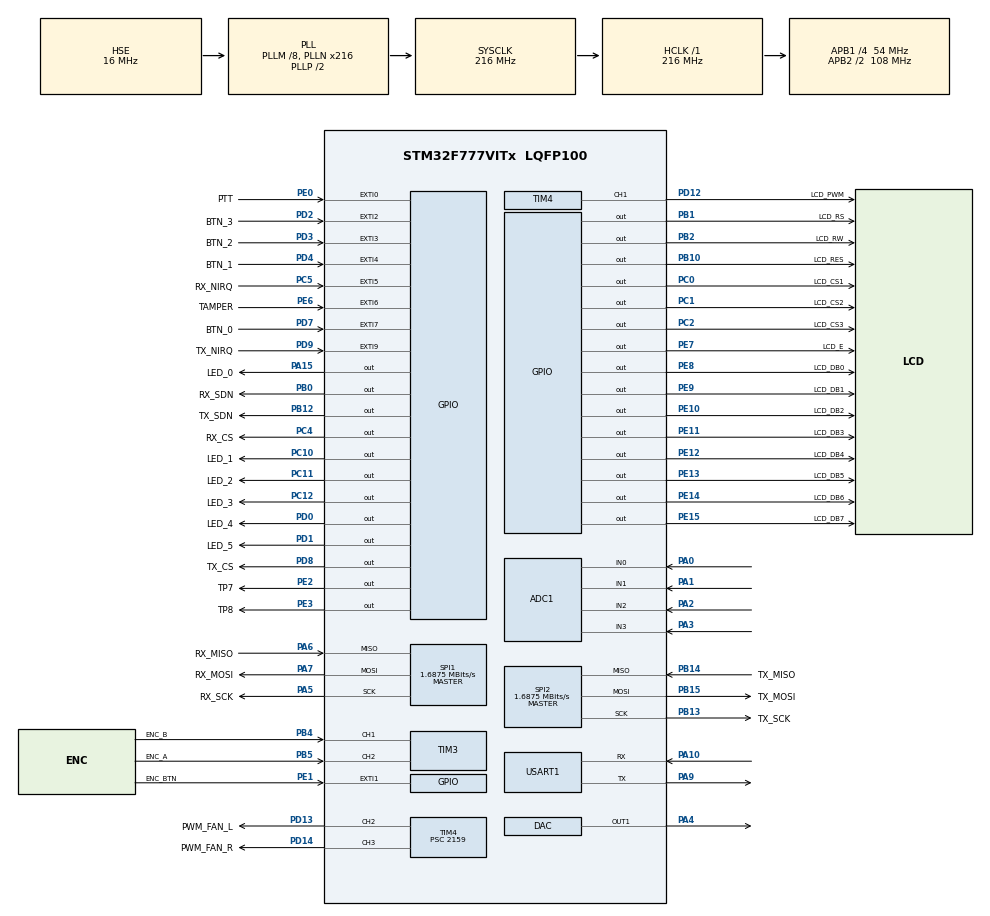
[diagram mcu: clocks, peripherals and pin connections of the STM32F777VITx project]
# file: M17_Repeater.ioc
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ADC1.Channel-0\#ChannelRegularConversion=ADC_CHANNEL_0
ADC1.NbrOfConversionFlag=1
ADC1.Rank-0\#ChannelRegularConversion=1
ADC1.SamplingTime-0\#ChannelRegularConversion=ADC_SAMPLETIME_3CYCLES
ADC1.master=1
Dma.Request0=USART1_TX
Dma.USART1_TX.0.Direction=DMA_MEMORY_TO_PERIPH
Dma.USART1_TX.0.FIFOMode=DMA_FIFOMODE_DISABLE
Dma.USART1_TX.0.Instance=DMA2_Stream7
Dma.USART1_TX.0.MemDataAlignment=DMA_MDATAALIGN_BYTE
Dma.USART1_TX.0.MemInc=DMA_MINC_ENABLE
Dma.USART1_TX.0.Mode=DMA_NORMAL
Dma.USART1_TX.0.PeriphDataAlignment=DMA_PDATAALIGN_BYTE
Dma.USART1_TX.0.PeriphInc=DMA_PINC_DISABLE
Dma.USART1_TX.0.Priority=DMA_PRIORITY_HIGH
Mcu.Family=STM32F7
Mcu.Name=STM32F777VITx
Mcu.Package=LQFP100
NVIC.DMA2_Stream7_IRQn=true\:0\:0\:false\:false\:true\:false
NVIC.EXTI0_IRQn=true\:0\:0\:false\:false\:true\:true
NVIC.EXTI1_IRQn=true\:0\:0\:false\:false\:true\:true
NVIC.EXTI2_IRQn=true\:0\:0\:false\:false\:true\:true
NVIC.EXTI3_IRQn=true\:0\:0\:false\:false\:true\:true
NVIC.EXTI4_IRQn=true\:0\:0\:false\:false\:true\:true
NVIC.EXTI9_5_IRQn=true\:0\:0\:false\:false\:true\:true
NVIC.PriorityGroup=NVIC_PRIORITYGROUP_4
NVIC.TIM6_DAC_IRQn=true\:0\:0\:false\:false\:true\:true
NVIC.USART1_IRQn=true\:0\:0\:false\:false\:true\:true
PA0/WKUP.Signal=ADCx_IN0
PA1.Signal=ADCx_IN1
PA10.Mode=Asynchronous
PA10.Signal=USART1_RX
PA13.Mode=Serial_Wire
PA13.Signal=SYS_JTMS-SWDIO
PA14.Mode=Serial_Wire
PA14.Signal=SYS_JTCK-SWCLK
PA15.GPIO_Label=LED_0
PA15.Signal=GPIO_Output
PA2.Signal=ADCx_IN2
PA3.Signal=ADCx_IN3
PA4.Signal=COMP_DAC1_group
PA5.GPIO_Label=RX_SCK
PA5.Mode=Full_Duplex_Master
PA5.Signal=SPI1_SCK
PA6.GPIO_Label=RX_MISO
PA6.Mode=Full_Duplex_Master
PA6.Signal=SPI1_MISO
PA7.GPIO_Label=RX_MOSI
PA7.Mode=Full_Duplex_Master
PA7.Signal=SPI1_MOSI
PA9.Mode=Asynchronous
PA9.Signal=USART1_TX
PB0.GPIO_Label=RX_SDN
PB0.GPIO_ModeDefaultOutputPP=GPIO_MODE_OUTPUT_PP
PB0.GPIO_PuPd=GPIO_NOPULL
PB0.GPIO_Speed=GPIO_SPEED_FREQ_VERY_HIGH
PB0.PinState=GPIO_PIN_SET
PB0.Signal=GPIO_Output
PB1.GPIO_Label=LCD_RS
PB1.GPIO_ModeDefaultOutputPP=GPIO_MODE_OUTPUT_PP
PB1.GPIO_PuPd=GPIO_NOPULL
PB1.GPIO_Speed=GPIO_SPEED_FREQ_VERY_HIGH
PB1.Signal=GPIO_Output
PB10.GPIO_Label=LCD_RES
PB10.GPIO_ModeDefaultOutputPP=GPIO_MODE_OUTPUT_PP
PB10.GPIO_PuPd=GPIO_NOPULL
PB10.GPIO_Speed=GPIO_SPEED_FREQ_VERY_HIGH
PB10.Signal=GPIO_Output
PB12.GPIO_Label=TX_SDN
PB12.GPIO_ModeDefaultOutputPP=GPIO_MODE_OUTPUT_PP
PB12.GPIO_PuPd=GPIO_NOPULL
PB12.GPIO_Speed=GPIO_SPEED_FREQ_VERY_HIGH
PB12.PinState=GPIO_PIN_SET
PB12.Signal=GPIO_Output
PB13.GPIO_Label=TX_SCK
PB13.Mode=Full_Duplex_Master
PB13.Signal=SPI2_SCK
PB14.GPIO_Label=TX_MISO
PB14.Mode=Full_Duplex_Master
PB14.Signal=SPI2_MISO
PB15.GPIO_Label=TX_MOSI
PB15.Mode=Full_Duplex_Master
PB15.Signal=SPI2_MOSI
PB2.GPIO_Label=LCD_RW
PB2.GPIO_ModeDefaultOutputPP=GPIO_MODE_OUTPUT_PP
PB2.GPIO_PuPd=GPIO_NOPULL
PB2.GPIO_Speed=GPIO_SPEED_FREQ_VERY_HIGH
PB2.Signal=GPIO_Output
PB4.GPIO_Label=ENC_B
PB4.Signal=S_TIM3_CH1
PB5.GPIO_Label=ENC_A
PB5.Signal=S_TIM3_CH2
PC0.GPIO_Label=LCD_CS1
PC0.GPIO_Speed=GPIO_SPEED_FREQ_VERY_HIGH
PC0.Signal=GPIO_Output
PC1.GPIO_Label=LCD_CS2
PC1.GPIO_Speed=GPIO_SPEED_FREQ_VERY_HIGH
PC1.Signal=GPIO_Output
PC10.GPIO_Label=LED_1
PC10.Signal=GPIO_Output
PC11.GPIO_Label=LED_2
PC11.Signal=GPIO_Output
PC12.GPIO_Label=LED_3
PC12.Signal=GPIO_Output
PC2.GPIO_Label=LCD_CS3
PC2.GPIO_Speed=GPIO_SPEED_FREQ_VERY_HIGH
PC2.Signal=GPIO_Output
PC4.GPIO_Label=RX_CS
PC4.GPIO_Speed=GPIO_SPEED_FREQ_VERY_HIGH
PC4.PinState=GPIO_PIN_SET
PC4.Signal=GPIO_Output
PC5.GPIO_Label=RX_NIRQ
PC5.GPIO_ModeDefaultEXTI=GPIO_MODE_IT_FALLING
PC5.Signal=GPXTI5
PD0.GPIO_Label=LED_4
PD0.Signal=GPIO_Output
PD1.GPIO_Label=LED_5
PD1.Signal=GPIO_Output
PD12.GPIO_Label=LCD_PWM
PD12.GPIO_Speed=GPIO_SPEED_FREQ_HIGH
PD12.Signal=S_TIM4_CH1
PD13.GPIO_Label=PWM_FAN_L
PD13.GPIO_ModeDefaultPP=GPIO_MODE_AF_PP
PD13.GPIO_PuPd=GPIO_NOPULL
PD13.GPIO_Speed=GPIO_SPEED_FREQ_HIGH
PD13.Signal=S_TIM4_CH2
PD14.GPIO_Label=PWM_FAN_R
PD14.GPIO_ModeDefaultPP=GPIO_MODE_AF_PP
PD14.GPIO_PuPd=GPIO_NOPULL
PD14.GPIO_Speed=GPIO_SPEED_FREQ_HIGH
PD14.Signal=S_TIM4_CH3
PD2.GPIO_Label=BTN_3
PD2.GPIO_ModeDefaultEXTI=GPIO_MODE_IT_FALLING
PD2.GPIO_PuPd=GPIO_NOPULL
PD2.Signal=GPXTI2
PD3.GPIO_Label=BTN_2
PD3.GPIO_ModeDefaultEXTI=GPIO_MODE_IT_FALLING
PD3.GPIO_PuPd=GPIO_NOPULL
PD3.Signal=GPXTI3
PD4.GPIO_Label=BTN_1
PD4.GPIO_ModeDefaultEXTI=GPIO_MODE_IT_FALLING
PD4.GPIO_PuPd=GPIO_NOPULL
PD4.Signal=GPXTI4
PD7.GPIO_Label=BTN_0
PD7.GPIO_ModeDefaultEXTI=GPIO_MODE_IT_FALLING
PD7.GPIO_PuPd=GPIO_NOPULL
PD7.Signal=GPXTI7
PD8.GPIO_Label=TX_CS
PD8.GPIO_Speed=GPIO_SPEED_FREQ_VERY_HIGH
PD8.PinState=GPIO_PIN_SET
PD8.Signal=GPIO_Output
PD9.GPIO_Label=TX_NIRQ
PD9.GPIO_ModeDefaultEXTI=GPIO_MODE_IT_FALLING
PD9.Signal=GPXTI9
PE0.GPIO_Label=PTT
PE0.GPIO_ModeDefaultEXTI=GPIO_MODE_IT_FALLING
PE0.Signal=GPXTI0
PE1.GPIO_Label=ENC_BTN
PE1.GPIO_ModeDefaultEXTI=GPIO_MODE_IT_FALLING
PE1.Signal=GPXTI1
PE10.GPIO_Label=LCD_DB2
PE10.GPIO_ModeDefaultOutputPP=GPIO_MODE_OUTPUT_PP
PE10.GPIO_PuPd=GPIO_NOPULL
PE10.GPIO_Speed=GPIO_SPEED_FREQ_VERY_HIGH
PE10.PinState=GPIO_PIN_RESET
PE10.Signal=GPIO_Output
PE11.GPIO_Label=LCD_DB3
PE11.GPIO_ModeDefaultOutputPP=GPIO_MODE_OUTPUT_PP
PE11.GPIO_PuPd=GPIO_NOPULL
PE11.GPIO_Speed=GPIO_SPEED_FREQ_VERY_HIGH
PE11.PinState=GPIO_PIN_RESET
PE11.Signal=GPIO_Output
PE12.GPIO_Label=LCD_DB4
PE12.GPIO_ModeDefaultOutputPP=GPIO_MODE_OUTPUT_PP
PE12.GPIO_PuPd=GPIO_NOPULL
PE12.GPIO_Speed=GPIO_SPEED_FREQ_VERY_HIGH
PE12.PinState=GPIO_PIN_RESET
PE12.Signal=GPIO_Output
PE13.GPIO_Label=LCD_DB5
PE13.GPIO_ModeDefaultOutputPP=GPIO_MODE_OUTPUT_PP
PE13.GPIO_PuPd=GPIO_NOPULL
PE13.GPIO_Speed=GPIO_SPEED_FREQ_VERY_HIGH
PE13.PinState=GPIO_PIN_RESET
PE13.Signal=GPIO_Output
PE14.GPIO_Label=LCD_DB6
PE14.GPIO_ModeDefaultOutputPP=GPIO_MODE_OUTPUT_PP
PE14.GPIO_PuPd=GPIO_NOPULL
PE14.GPIO_Speed=GPIO_SPEED_FREQ_VERY_HIGH
PE14.PinState=GPIO_PIN_RESET
PE14.Signal=GPIO_Output
PE15.GPIO_Label=LCD_DB7
PE15.GPIO_ModeDefaultOutputPP=GPIO_MODE_OUTPUT_PP
PE15.GPIO_PuPd=GPIO_NOPULL
PE15.GPIO_Speed=GPIO_SPEED_FREQ_VERY_HIGH
PE15.PinState=GPIO_PIN_RESET
PE15.Signal=GPIO_Output
PE2.GPIO_Label=TP7
PE2.Signal=GPIO_Output
PE3.GPIO_Label=TP8
PE3.Signal=GPIO_Output
PE6.GPIO_Label=TAMPER
PE6.GPIO_ModeDefaultEXTI=GPIO_MODE_IT_RISING_FALLING
PE6.Signal=GPXTI6
PE7.GPIO_Label=LCD_E
PE7.GPIO_ModeDefaultOutputPP=GPIO_MODE_OUTPUT_PP
PE7.GPIO_PuPd=GPIO_NOPULL
PE7.GPIO_Speed=GPIO_SPEED_FREQ_VERY_HIGH
PE7.PinState=GPIO_PIN_RESET
PE7.Signal=GPIO_Output
PE8.GPIO_Label=LCD_DB0
PE8.GPIO_ModeDefaultOutputPP=GPIO_MODE_OUTPUT_PP
PE8.GPIO_PuPd=GPIO_NOPULL
PE8.GPIO_Speed=GPIO_SPEED_FREQ_VERY_HIGH
PE8.PinState=GPIO_PIN_RESET
PE8.Signal=GPIO_Output
PE9.GPIO_Label=LCD_DB1
PE9.GPIO_ModeDefaultOutputPP=GPIO_MODE_OUTPUT_PP
PE9.GPIO_PuPd=GPIO_NOPULL
PE9.GPIO_Speed=GPIO_SPEED_FREQ_VERY_HIGH
PE9.PinState=GPIO_PIN_RESET
PE9.Signal=GPIO_Output
PH0/OSC_IN.Mode=HSE-External-Clock-Source
PH0/OSC_IN.Signal=RCC_OSC_IN
PH1/OSC_OUT.Mode=HSE-External-Clock-Source
PH1/OSC_OUT.Signal=RCC_OSC_OUT
ProjectManager.HeapSize=0x200
ProjectManager.StackSize=0x400
ProjectManager.TargetToolchain=SW4STM32
RCC.AHBFreq_Value=216000000
RCC.APB1CLKDivider=RCC_HCLK_DIV4
RCC.APB1Freq_Value=54000000
RCC.APB1TimFreq_Value=108000000
RCC.APB2CLKDivider=RCC_HCLK_DIV2
RCC.APB2Freq_Value=108000000
RCC.APB2TimFreq_Value=216000000
RCC.CortexFreq_Value=216000000
RCC.HCLKFreq_Value=216000000
RCC.HSE_VALUE=16000000
RCC.HSI_VALUE=16000000
RCC.LSE_VALUE=32768
RCC.PLLM=8
RCC.PLLN=216
RCC.PLLSourceVirtual=RCC_PLLSOURCE_HSE
RCC.SYSCLKFreq_VALUE=216000000
RCC.SYSCLKSource=RCC_SYSCLKSOURCE_PLLCLK
RCC.USBFreq_Value=216000000
RCC.VCOOutputFreq_Value=432000000
SH.ADCx_IN0.0=ADC1_IN0,IN0
SH.ADCx_IN1.0=ADC1_IN1,IN1
SH.ADCx_IN2.0=ADC1_IN2,IN2
SH.ADCx_IN3.0=ADC1_IN3,IN3
SH.COMP_DAC1_group.0=DAC_OUT1,DAC_OUT1
SH.S_TIM3_CH1.0=TIM3_CH1,Encoder_Interface
SH.S_TIM3_CH2.0=TIM3_CH2,Encoder_Interface
SH.S_TIM4_CH1.0=TIM4_CH1,PWM Generation1 CH1
SH.S_TIM4_CH2.0=TIM4_CH2,PWM Generation2 CH2
SH.S_TIM4_CH3.0=TIM4_CH3,PWM Generation3 CH3
SPI1.BaudRatePrescaler=SPI_BAUDRATEPRESCALER_64
SPI1.CalculateBaudRate=1.6875 MBits/s
SPI1.DataSize=SPI_DATASIZE_8BIT
SPI1.Direction=SPI_DIRECTION_2LINES
SPI1.Mode=SPI_MODE_MASTER
SPI1.NSSPMode=SPI_NSS_PULSE_DISABLE
SPI1.VirtualType=VM_MASTER
SPI2.BaudRatePrescaler=SPI_BAUDRATEPRESCALER_32
SPI2.CalculateBaudRate=1.6875 MBits/s
SPI2.DataSize=SPI_DATASIZE_8BIT
SPI2.Direction=SPI_DIRECTION_2LINES
SPI2.Mode=SPI_MODE_MASTER
SPI2.NSSPMode=SPI_NSS_PULSE_DISABLE
SPI2.VirtualType=VM_MASTER
TIM4.Channel-PWM\ Generation1\ CH1=TIM_CHANNEL_1
TIM4.Channel-PWM\ Generation2\ CH2=TIM_CHANNEL_2
TIM4.Channel-PWM\ Generation3\ CH3=TIM_CHANNEL_3
TIM4.Period=99
TIM4.Prescaler=2159
TIM4.Pulse-PWM\ Generation1\ CH1=0
TIM6.Period=1999
TIM6.Prescaler=21599
TIM6.TIM_MasterOutputTrigger=TIM_TRGO_UPDATE
USART1.VirtualMode-Asynchronous=VM_ASYNC
VP_TIM4_VS_ClockSourceINT.Mode=Internal
VP_TIM6_VS_ClockSourceINT.Mode=Enable_Timer
board=custom

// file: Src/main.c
/**
  ******************************************************************************
  * @file           : main.c
  * @brief          : Main program body
  ******************************************************************************
  ** This notice applies to any and all portions of this file
  * that are not between comment pairs USER CODE BEGIN and
  * USER CODE END. Other portions of this file, whether
  * inserted by the user or by software development tools
  * are owned by their respective copyright owners.
  *
  * COPYRIGHT(c) 2019 STMicroelectronics
  *
  * Redistribution and use in source and binary forms, with or without modification,
  * are permitted provided that the following conditions are met:
  *   1. Redistributions of source code must retain the above copyright notice,
  *      this list of conditions and the following disclaimer.
  *   2. Redistributions in binary form must reproduce the above copyright notice,
  *      this list of conditions and the following disclaimer in the documentation
  *      and/or other materials provided with the distribution.
  *   3. Neither the name of STMicroelectronics nor the names of its contributors
  *      may be used to endorse or promote products derived from this software
  *      without specific prior written permission.
  *
  * THIS SOFTWARE IS PROVIDED BY THE COPYRIGHT HOLDERS AND CONTRIBUTORS "AS IS"
  * AND ANY EXPRESS OR IMPLIED WARRANTIES, INCLUDING, BUT NOT LIMITED TO, THE
  * IMPLIED WARRANTIES OF MERCHANTABILITY AND FITNESS FOR A PARTICULAR PURPOSE ARE
  * DISCLAIMED. IN NO EVENT SHALL THE COPYRIGHT HOLDER OR CONTRIBUTORS BE LIABLE
  * FOR ANY DIRECT, INDIRECT, INCIDENTAL, SPECIAL, EXEMPLARY, OR CONSEQUENTIAL
  * DAMAGES (INCLUDING, BUT NOT LIMITED TO, PROCUREMENT OF SUBSTITUTE GOODS OR
  * SERVICES; LOSS OF USE, DATA, OR PROFITS; OR BUSINESS INTERRUPTION) HOWEVER
  * CAUSED AND ON ANY THEORY OF LIABILITY, WHETHER IN CONTRACT, STRICT LIABILITY,
  * OR TORT (INCLUDING NEGLIGENCE OR OTHERWISE) ARISING IN ANY WAY OUT OF THE USE
  * OF THIS SOFTWARE, EVEN IF ADVISED OF THE POSSIBILITY OF SUCH DAMAGE.
  *
  ******************************************************************************
  */
#include "main.h"
#include "stm32f7xx_hal.h"

/* USER CODE BEGIN Includes */
#include "font.h"

#include "radio_config.h"

#define	FRAMESIZE		160*2					//20+20=40ms frame
#define	RAW_BYTES		8*2
#define	CRC_LEN			2
#define	ENC_LEN			(RAW_BYTES)*2
#define	PLOAD_LEN		93

#define	DC_OFFSET		2040					//input signal DC offset

#define	MAX_TX_POWER	0x7F					//+20dBm

#define SPLIT			7600000UL				//TX-RX split

#define UART_BUFF_LEN	130						//UART1 buffer length
/* USER CODE END Includes */

ADC_HandleTypeDef hadc1;

DAC_HandleTypeDef hdac;

SPI_HandleTypeDef hspi1;
SPI_HandleTypeDef hspi2;

TIM_HandleTypeDef htim3;
TIM_HandleTypeDef htim4;
TIM_HandleTypeDef htim6;

UART_HandleTypeDef huart1;
DMA_HandleTypeDef hdma_usart1_tx;

/* USER CODE BEGIN PV */
/* Private variables ---------------------------------------------------------*/
//Si 446x RELATED
const uint8_t config[] = RADIO_CONFIGURATION_DATA_ARRAY;	//config
volatile uint8_t RX_ints[8];								//interrupts
volatile uint8_t r_initd=0;									//RX initialized?

volatile uint8_t rcv_buff[PLOAD_LEN];						//Si RX buffer

//main
volatile uint32_t tx_freq=439075000;						//TX frequency in Hz
volatile uint32_t rx_freq=431475000;						//RX

//QSO
volatile uint32_t last_id_from=0;
volatile uint32_t last_id_to=0;
volatile uint8_t  content_type=0;
volatile uint8_t  encr_type=0;

//UART
volatile uint8_t rx_buff[UART_BUFF_LEN];
volatile uint8_t tx_buff[UART_BUFF_LEN];
volatile uint8_t rx_cnt=0;									//where in rx buffer are we?

//TIMERS
volatile uint8_t tim_6_initd=0;								//first tim6 irq cleared?
/* USER CODE END PV */

void SystemClock_Config(void);
static void MX_GPIO_Init(void);
static void MX_DMA_Init(void);
static void MX_ADC1_Init(void);
static void MX_DAC_Init(void);
static void MX_SPI2_Init(void);
static void MX_TIM4_Init(void);
static void MX_USART1_UART_Init(void);
static void MX_SPI1_Init(void);
static void MX_TIM3_Init(void);
static void MX_TIM6_Init(void);

void HAL_TIM_MspPostInit(TIM_HandleTypeDef *htim);

/* USER CODE BEGIN PFP */
/* Private function prototypes -----------------------------------------------*/
//------------------------------SPI1 - Si4463 - RX------------------------------
void RX_WaitForCTS(void)
{
	uint8_t cts[1]={0x00};
	const uint8_t dta[1]={0x44};

	do
	{
		HAL_GPIO_WritePin(RX_CS_GPIO_Port, RX_CS_Pin, 0);
		HAL_SPI_Transmit(&hspi1, dta, 1, 100);
		HAL_SPI_Receive(&hspi1, cts, 1, 100);
		//if(cts[0]!=0xFF)
			HAL_GPIO_WritePin(RX_CS_GPIO_Port, RX_CS_Pin, 1);
	}while(cts[0]!=0xFF);
}

void RX_Send(uint8_t *data, uint8_t len)
{
	RX_WaitForCTS();
	HAL_GPIO_WritePin(RX_CS_GPIO_Port, RX_CS_Pin, 0);
	HAL_SPI_Transmit(&hspi1, data, len, 100);
	HAL_GPIO_WritePin(RX_CS_GPIO_Port, RX_CS_Pin, 1);
}

void RX_GetResponse(uint8_t len, uint8_t *data)
{
	uint8_t cts[1]={0x00};
	uint8_t dta[1]={0x44};

	while(cts[0]!=0xFF)
	{
		HAL_GPIO_WritePin(RX_CS_GPIO_Port, RX_CS_Pin, 0);
		HAL_SPI_Transmit(&hspi1, dta, 1, 100);
		HAL_SPI_Receive(&hspi1, cts, 1, 1);

		if(cts[0]!=0xFF)
			HAL_GPIO_WritePin(RX_CS_GPIO_Port, RX_CS_Pin, 1);
	}

	HAL_SPI_Receive(&hspi1, data, len, 100);

	HAL_GPIO_WritePin(RX_CS_GPIO_Port, RX_CS_Pin, 1);
}

void RX_ReadRxDataBuff(uint8_t len, uint8_t *data)
{
	uint8_t cmd[1]={0x77};

	HAL_GPIO_WritePin(RX_CS_GPIO_Port, RX_CS_Pin, 0);
	HAL_SPI_Transmit(&hspi1, cmd, 1, 100);
	HAL_SPI_Receive(&hspi1, data, len, 100);
	HAL_GPIO_WritePin(RX_CS_GPIO_Port, RX_CS_Pin, 1);
}

//------------------------------SPI2 - Si4463 - TX------------------------------
void TX_WaitForCTS(void)
{
	uint8_t cts[1]={0x00};
	const uint8_t dta[1]={0x44};

	do
	{
		HAL_GPIO_WritePin(TX_CS_GPIO_Port, TX_CS_Pin, 0);
		HAL_SPI_Transmit(&hspi2, dta, 1, 100);
		HAL_SPI_Receive(&hspi2, cts, 1, 100);
		//if(cts[0]!=0xFF)
			HAL_GPIO_WritePin(TX_CS_GPIO_Port, TX_CS_Pin, 1);
	}while(cts[0]!=0xFF);
}

void TX_Send(uint8_t *data, uint8_t len)
{
	TX_WaitForCTS();
	HAL_GPIO_WritePin(TX_CS_GPIO_Port, TX_CS_Pin, 0);
	HAL_SPI_Transmit(&hspi2, data, len, 100);
	HAL_GPIO_WritePin(TX_CS_GPIO_Port, TX_CS_Pin, 1);
}

void TX_GetResponse(uint8_t len, uint8_t *data)
{
	uint8_t cts[1]={0x00};
	uint8_t dta[1]={0x44};

	while(cts[0]!=0xFF)
	{
		HAL_GPIO_WritePin(TX_CS_GPIO_Port, TX_CS_Pin, 0);
		HAL_SPI_Transmit(&hspi2, dta, 1, 100);
		HAL_SPI_Receive(&hspi2, cts, 1, 1);

		if(cts[0]!=0xFF)
			HAL_GPIO_WritePin(TX_CS_GPIO_Port, TX_CS_Pin, 1);
	}

	HAL_SPI_Receive(&hspi2, data, len, 100);

	HAL_GPIO_WritePin(TX_CS_GPIO_Port, TX_CS_Pin, 1);
}

void TX_WriteTxDataBuff(uint8_t *data, uint8_t len)
{
	uint8_t cmd = 0x66;

	HAL_GPIO_WritePin(TX_CS_GPIO_Port, TX_CS_Pin, 0);
	HAL_SPI_Transmit(&hspi2, &cmd, 1, 100);
	HAL_SPI_Transmit(&hspi2, data, len, 100);
	HAL_GPIO_WritePin(TX_CS_GPIO_Port, TX_CS_Pin, 1);
}

//------------------------------RX Si4463 FUNCS------------------------------
void RX_Reset(void)
{
	HAL_GPIO_WritePin(RX_SDN_GPIO_Port, RX_SDN_Pin, 1);
	HAL_Delay(5);
	HAL_GPIO_WritePin(RX_SDN_GPIO_Port, RX_SDN_Pin, 0);
	HAL_Delay(5);
}

static void RX_SetProp(uint8_t* vals, uint8_t group, uint8_t number, uint8_t len)
{
	uint8_t data[16]={0x11,	group, len, number};

	memcpy(data + 4, vals, len);

	RX_WaitForCTS();
	RX_Send(data, len + 4);
}

static void RX_StartupConfig(void)
{
	uint8_t buff[17];

	for(uint16_t i=0; i<sizeof(config); i++)
	{
		memcpy(buff, &config[i], sizeof(buff));
		RX_WaitForCTS();
		RX_Send(&buff[1], buff[0]);
		i += buff[0];
	}
}

static void RX_Interrupts(void* buff)
{
	uint8_t data = 0x20;

	RX_Send(&data, 1);
	if(buff!=NULL)
		RX_GetResponse(8, buff);
}

/*static void RX_InterruptsNoCTS(void* buff)
{
	uint8_t v = 0x20;

	HAL_GPIO_WritePin(RX_CS_GPIO_Port, RX_CS_Pin, 0);
	HAL_SPI_Transmit(&hspi1, &v, 1, 100);
	HAL_SPI_Receive(&hspi1, buff, 8, 100);
	HAL_GPIO_WritePin(RX_CS_GPIO_Port, RX_CS_Pin, 1);
}*/

static void RX_Interrupts2(void* buff, uint8_t clearPH, uint8_t clearMODEM, uint8_t clearCHIP)
{
	uint8_t data[] = {
		0x20,
		clearPH,
		clearMODEM,
		clearCHIP
	};

	RX_Send(data, 4);
	if(buff!=NULL)
		RX_GetResponse(8, buff);
}

static uint8_t RX_GetState(void)
{
	uint8_t state[2]={0, 0};
	uint8_t get_state_cmd=0x33;

	RX_WaitForCTS();
	RX_Send(&get_state_cmd, 1);
	RX_GetResponse(2, state);

	return state[0]&0x0F;
}

static void RX_SetState(uint8_t newState)
{
	uint8_t data[2]={0x34, newState};

	RX_Send(data, 2);
}

void RX_Sleep(void)
{
	uint8_t state=RX_GetState();

	if(state==7 || state==5)
		return;

	RX_SetState(1);
}

void RX_ClearFIFO(uint8_t fifos)
{
	uint8_t msg[3]={0x15, fifos};

	RX_Send(&msg, 2);
}

void RX_StartRx(uint8_t ch, uint8_t len)
{
	//RX_SetState(3);		//RX state
	RX_ClearFIFO(3);	//clear both FIFOs
	//RX_Interrupts2(NULL, 0, 0, 0xFF);	//clear some interrupts

	uint8_t msg[8]={0x32, ch, 0, 0, len, 0x08, 0x08, 0x08};

	RX_Send(msg, 8);
}

void RX_FreqSet(uint32_t freq)	//freq in Hz
{
	uint8_t inte=0x3C;	//default values
	uint64_t frac=0x00080000;

	freq=freq*(30.0/32.0);
	inte=freq/7500000-1;
	frac=(freq-(uint32_t)(inte+1)*7500000)/75;
	frac=(uint64_t)frac*(1<<19)/100000+(uint32_t)(1<<19);

	uint8_t vals[4]={inte, (frac>>16)&0xFF, (frac>>8)&0xFF, frac&0xFF};

	RX_SetProp(&vals, 0x40, 0x00, 4);
}

uint8_t RX_GetRSSI(void)
{
	uint8_t v=0x50;
	uint8_t r[4];

	HAL_GPIO_WritePin(RX_CS_GPIO_Port, RX_CS_Pin, 0);
	HAL_SPI_Transmit(&hspi1, &v, 1, 100);
	HAL_SPI_Receive(&hspi1, r, 4, 100);
	HAL_GPIO_WritePin(RX_CS_GPIO_Port, RX_CS_Pin, 1);

	return r[0];
}

void RX_GetInfo(uint8_t *resp)
{
	uint8_t cmd=0x01;

	RX_Send(&cmd, 1);
	RX_WaitForCTS();
	RX_GetResponse(8, resp);
}

uint8_t RX_Check(void)
{
	uint8_t info[8];

	RX_GetInfo(info);

	if(info[1]==0x44 && info[2]==0x63)
		return 0;

	return 1;
}

//------------------------------TX Si4463 FUNCS------------------------------
void TX_Reset(void)
{
	HAL_GPIO_WritePin(TX_SDN_GPIO_Port, TX_SDN_Pin, 1);
	HAL_Delay(5);
	HAL_GPIO_WritePin(TX_SDN_GPIO_Port, TX_SDN_Pin, 0);
	HAL_Delay(5);
}

static void TX_SetProp(uint8_t* vals, uint8_t group, uint8_t number, uint8_t len)
{
	uint8_t data[16]={0x11,	group, len, number};

	memcpy(data + 4, vals, len);

	TX_WaitForCTS();
	TX_Send(data, len + 4);
}

static void TX_StartupConfig(void)
{
	uint8_t buff[17];

	for(uint16_t i=0; i<sizeof(config); i++)
	{
		memcpy(buff, &config[i], sizeof(buff));
		TX_WaitForCTS();
		TX_Send(&buff[1], buff[0]);
		i += buff[0];
	}
}

static void TX_Interrupts(void* buff)
{
	uint8_t data = 0x20;

	TX_Send(&data, 1);
	if(buff!=NULL)
		TX_GetResponse(8, buff);
}

/*static void TX_InterruptsNoCTS(void* buff)
{
	uint8_t v = 0x20;

	HAL_GPIO_WritePin(TX_CS_GPIO_Port, TX_CS_Pin, 0);
	HAL_SPI_Transmit(&hspi2, &v, 1, 100);
	HAL_SPI_Receive(&hspi21, buff, 8, 100);
	HAL_GPIO_WritePin(TX_CS_GPIO_Port, TX_CS_Pin, 1);
}*/

static void TX_Interrupts2(void* buff, uint8_t clearPH, uint8_t clearMODEM, uint8_t clearCHIP)
{
	uint8_t data[] = {
		0x20,
		clearPH,
		clearMODEM,
		clearCHIP
	};

	TX_Send(data, 4);
	if(buff!=NULL)
		TX_GetResponse(8, buff);
}

static uint8_t TX_GetState(void)
{
	uint8_t state[2]={0, 0};
	uint8_t get_state_cmd=0x33;

	TX_WaitForCTS();
	TX_Send(&get_state_cmd, 1);
	TX_GetResponse(2, state);

	return state[0]&0x0F;
}

static void TX_SetState(uint8_t newState)
{
	uint8_t data[2]={0x34, newState};

	TX_Send(data, 2);
}

void TX_Sleep(void)
{
	uint8_t state=TX_GetState();

	if(state==7 || state==5)
		return;

	TX_SetState(1);
}

void TX_ClearFIFO(uint8_t fifos)
{
	uint8_t msg[3]={0x15, fifos};

	TX_Send(&msg, 2);
}

void TX_SetTxPower(uint8_t pwr)
{
	/*uint8_t msg[5]={0x11, 0x22, 0x01, 0x01, pwr};

	TX_Send(&msg, 5);*/
	TX_SetProp(&pwr, 0x22, 0x01, 1);
}

void TX_StartTx(uint8_t ch, uint8_t end_state, uint8_t tx_len)
{
	uint8_t msg[7]={0x31, ch, (uint8_t)end_state<<4, 0, tx_len, 0, 0};

	TX_WaitForCTS();
	TX_Send(&msg, 7);
}

void TX_TxData(uint8_t *d, uint8_t len, uint8_t ch)
{
	TX_ClearFIFO(3);
	TX_Interrupts2(NULL, 0, 0, 0xFF);

	TX_WriteTxDataBuff(d, len);
	TX_StartTx(ch, 3, len);	//3 - READY state after TX complete
}

void TX_FreqSet(uint32_t freq)	//freq in Hz
{
	uint8_t inte=0x3C;	//default values
	uint64_t frac=0x00080000;

	freq=freq*(30.0/32.0);
	inte=freq/7500000-1;
	frac=(freq-(uint32_t)(inte+1)*7500000)/75;
	frac=(uint64_t)frac*(1<<19)/100000+(uint32_t)(1<<19);

	uint8_t vals[4]={inte, (frac>>16)&0xFF, (frac>>8)&0xFF, frac&0xFF};

	TX_SetProp(&vals, 0x40, 0x00, 4);
}

void TX_GetInfo(uint8_t *resp)
{
	uint8_t cmd=0x01;

	TX_Send(&cmd, 1);
	TX_WaitForCTS();
	TX_GetResponse(8, resp);
}

uint8_t TX_Check(void)
{
	uint8_t info[8];

	TX_GetInfo(info);

	if(info[1]==0x44 && info[2]==0x63)
		return 0;

	return 1;
}

//----------------------------------MISC FUNCS---------------------------------
void Delay(uint32_t val)
{
	for(uint32_t i=0; i<val; i++)
		__ASM volatile("NOP");
}

//----------------------------------LCD FUNCS----------------------------------
/*void LCD_Wait(void)
{
	HAL_GPIO_WritePin(RS_GPIO_Port, RS_Pin, 0);
	for(uint8_t i=0; i<100; i++);
	HAL_GPIO_WritePin(RW_GPIO_Port, RW_Pin, 1);
	for(uint8_t i=0; i<100; i++);
	GPIOD->MODER&=~0x0000;
	while((GPIOD->IDR)&0x80);
	GPIOD->MODER=0x5555;
}*/

void LCD_Init(void)
{
	HAL_GPIO_WritePin(LCD_E_GPIO_Port, LCD_E_Pin, 0);
	HAL_Delay(5);
	HAL_GPIO_WritePin(LCD_RES_GPIO_Port, LCD_RES_Pin, 1);
	HAL_Delay(50);
	HAL_GPIO_WritePin(LCD_RES_GPIO_Port, LCD_RES_Pin, 0);
	HAL_Delay(250);
	HAL_GPIO_WritePin(LCD_RES_GPIO_Port, LCD_RES_Pin, 1);
	HAL_Delay(50);
}
void LCD_SetX(uint8_t x)
{
	HAL_GPIO_WritePin(LCD_RS_GPIO_Port, LCD_RS_Pin, 0);
	HAL_GPIO_WritePin(LCD_RW_GPIO_Port, LCD_RW_Pin, 0);
	Delay(200);
	GPIOE->ODR&=0x00FF; GPIOE->ODR|=(uint32_t)(0b10111000|x)<<8;
	Delay(200);
	HAL_GPIO_WritePin(LCD_E_GPIO_Port, LCD_E_Pin, 1);
	Delay(200);
	HAL_GPIO_WritePin(LCD_E_GPIO_Port, LCD_E_Pin, 0);
	Delay(200);
}

void LCD_SetY(uint8_t y)
{
	HAL_GPIO_WritePin(LCD_RS_GPIO_Port, LCD_RS_Pin, 0);
	HAL_GPIO_WritePin(LCD_RW_GPIO_Port, LCD_RW_Pin, 0);
	Delay(200);
	GPIOE->ODR&=0x00FF; GPIOE->ODR|=(uint32_t)(0b01000000|y)<<8;
	Delay(200);
	HAL_GPIO_WritePin(LCD_E_GPIO_Port, LCD_E_Pin, 1);
	Delay(200);
	HAL_GPIO_WritePin(LCD_E_GPIO_Port, LCD_E_Pin, 0);
	Delay(200);
}

void LCD_SetZ(uint8_t z)
{
	HAL_GPIO_WritePin(LCD_RS_GPIO_Port, LCD_RS_Pin, 0);
	HAL_GPIO_WritePin(LCD_RW_GPIO_Port, LCD_RW_Pin, 0);
	Delay(200);
	GPIOE->ODR&=0x00FF; GPIOE->ODR|=(uint32_t)(0b11000000|z)<<8;
	Delay(200);
	HAL_GPIO_WritePin(LCD_E_GPIO_Port, LCD_E_Pin, 1);
	Delay(200);
	HAL_GPIO_WritePin(LCD_E_GPIO_Port, LCD_E_Pin, 0);
	Delay(200);
}

void LCD_WriteData(uint8_t dta)
{
	HAL_GPIO_WritePin(LCD_RS_GPIO_Port, LCD_RS_Pin, 1);
	HAL_GPIO_WritePin(LCD_RW_GPIO_Port, LCD_RW_Pin, 0);
	Delay(200);
	GPIOE->ODR&=0x00FF; GPIOE->ODR|=(uint32_t)dta<<8;
	Delay(200);
	HAL_GPIO_WritePin(LCD_E_GPIO_Port, LCD_E_Pin, 1);
	Delay(200);
	HAL_GPIO_WritePin(LCD_E_GPIO_Port, LCD_E_Pin, 0);
	Delay(200);
}

void LCD_Disp(uint8_t ena)
{
	HAL_GPIO_WritePin(LCD_RS_GPIO_Port, LCD_RS_Pin, 0);
	HAL_GPIO_WritePin(LCD_RW_GPIO_Port, LCD_RW_Pin, 0);
	Delay(200);
	GPIOE->ODR&=0xFF00; GPIOE->ODR|=(uint32_t)(0b00111110|ena)<<8;
	Delay(200);
	HAL_GPIO_WritePin(LCD_E_GPIO_Port, LCD_E_Pin, 1);
	Delay(200);
	HAL_GPIO_WritePin(LCD_E_GPIO_Port, LCD_E_Pin, 0);
	Delay(200);
}

void LCD_Clear(void)
{
	HAL_GPIO_WritePin(LCD_CS1_GPIO_Port, LCD_CS1_Pin, 0);
	HAL_GPIO_WritePin(LCD_CS2_GPIO_Port, LCD_CS2_Pin, 0);
	HAL_GPIO_WritePin(LCD_CS3_GPIO_Port, LCD_CS3_Pin, 0);

	LCD_Disp(0);

	LCD_SetZ(0);

	for(uint8_t x=0; x<8; x++)
	{
		for(uint8_t y=0; y<64; y++)
		{
			LCD_SetX(x);
			LCD_SetY(y);
			LCD_WriteData(0);
		}
	}

	LCD_Disp(1);
}

//1 - 6x8; 2 - 12x16
void LCD_PutStrFast(uint8_t x, uint8_t y, uint8_t *str, uint8_t font)
{
	uint8_t k=0;
	LCD_SetZ(0);
	if(font==1)
	{
		for(uint j=0; j<strlen(str); j++)
		{
			for(uint8_t i=0; i<6; i++)
			{
				if((x+k+i)<64)
				{
					HAL_GPIO_WritePin(LCD_CS1_GPIO_Port, LCD_CS1_Pin, 0);
					HAL_GPIO_WritePin(LCD_CS2_GPIO_Port, LCD_CS2_Pin, 1);
					HAL_GPIO_WritePin(LCD_CS3_GPIO_Port, LCD_CS3_Pin, 1);
				}
				else if((x+k+i)<128)
				{
					HAL_GPIO_WritePin(LCD_CS1_GPIO_Port, LCD_CS1_Pin, 1);
					HAL_GPIO_WritePin(LCD_CS2_GPIO_Port, LCD_CS2_Pin, 0);
					HAL_GPIO_WritePin(LCD_CS3_GPIO_Port, LCD_CS3_Pin, 1);
				}
				else
				{
					HAL_GPIO_WritePin(LCD_CS1_GPIO_Port, LCD_CS1_Pin, 1);
					HAL_GPIO_WritePin(LCD_CS2_GPIO_Port, LCD_CS2_Pin, 1);
					HAL_GPIO_WritePin(LCD_CS3_GPIO_Port, LCD_CS3_Pin, 0);
				}

				LCD_SetX(y);
				LCD_SetY((x+k+i)%64);
				LCD_WriteData(font_6x8[str[j]][i]);
			}

			k+=6;
		}
	}
	else if(font==2)
	{
		for(uint j=0; j<strlen(str); j++)
		{
			for(uint8_t i=0; i<24; i++)
			{
				if((x+k+i/2)<64)
				{
					HAL_GPIO_WritePin(LCD_CS1_GPIO_Port, LCD_CS1_Pin, 0);
					HAL_GPIO_WritePin(LCD_CS2_GPIO_Port, LCD_CS2_Pin, 1);
					HAL_GPIO_WritePin(LCD_CS3_GPIO_Port, LCD_CS3_Pin, 1);
				}
				else if((x+k+i/2)<128)
				{
					HAL_GPIO_WritePin(LCD_CS1_GPIO_Port, LCD_CS1_Pin, 1);
					HAL_GPIO_WritePin(LCD_CS2_GPIO_Port, LCD_CS2_Pin, 0);
					HAL_GPIO_WritePin(LCD_CS3_GPIO_Port, LCD_CS3_Pin, 1);
				}
				else
				{
					HAL_GPIO_WritePin(LCD_CS1_GPIO_Port, LCD_CS1_Pin, 1);
					HAL_GPIO_WritePin(LCD_CS2_GPIO_Port, LCD_CS2_Pin, 1);
					HAL_GPIO_WritePin(LCD_CS3_GPIO_Port, LCD_CS3_Pin, 0);
				}

				LCD_SetX(y+i%2);
				LCD_SetY((x+k+i/2)%64);
				LCD_WriteData(font_12x16[str[j]][i]);
			}

			k+=12;
		}
	}
}

//------------------------------------PWMs-------------------------------------
void LCD_Blight(uint8_t perc)
{
	if(perc<101)
		TIM4->CCR1=perc;
	else
		TIM4->CCR1=100;

	HAL_TIM_PWM_Start(&htim4, TIM_CHANNEL_1);
}

/*void L_Fan_RPM(uint8_t perc)
{
	if(perc<101)
		TIM4->CCR2=perc;
	else
		TIM4->CCR2=100;

	HAL_TIM_PWM_Start(&htim4, TIM_CHANNEL_2);
}

void R_Fan_RPM(uint8_t perc)
{
	if(perc<101)
		TIM4->CCR3=perc;
	else
		TIM4->CCR3=100;

	HAL_TIM_PWM_Start(&htim4, TIM_CHANNEL_3);
}*/

//------------------------------------MISC-------------------------------------
void Tamper_check(void)
{
	if(HAL_GPIO_ReadPin(TAMPER_GPIO_Port, TAMPER_Pin))
	{
		LCD_PutStrFast(0, 7, "CASE OPEN", 1);
		HAL_GPIO_WritePin(LED_4_GPIO_Port, LED_4_Pin, 1);
	}
	else
	{
		LCD_PutStrFast(0, 7, "         ", 1);
		HAL_GPIO_WritePin(LED_4_GPIO_Port, LED_4_Pin, 0);
	}
}

HAL_StatusTypeDef HAL_UART_AbortReceive_IT(UART_HandleTypeDef *huart)
{
	/* Disable RXNE, PE and ERR (Frame error, noise error, overrun error) interrupts */
	CLEAR_BIT(huart->Instance->CR1, (USART_CR1_RXNEIE | USART_CR1_PEIE));
	CLEAR_BIT(huart->Instance->CR3, USART_CR3_EIE);

	/* Disable the UART DMA Rx request if enabled */
	if(HAL_IS_BIT_SET(huart->Instance->CR3, USART_CR3_DMAR))
	{
		CLEAR_BIT(huart->Instance->CR3, USART_CR3_DMAR);

		/* Abort the UART DMA Rx channel : use blocking DMA Abort API (no callback) */
		//if(huart->hdmarx != NULL)
		{
			/* Set the UART DMA Abort callback :
 	 	 	 will lead to call HAL_UART_AbortCpltCallback() at end of DMA abort procedure */
			//huart->hdmarx->XferAbortCallback = UART_DMARxOnlyAbortCallback;

			/* Abort DMA RX */
			//if(HAL_DMA_Abort_IT(huart->hdmarx) != HAL_OK)
			{
				/* Call Directly huart->hdmarx->XferAbortCallback function in case of error */
				//huart->hdmarx->XferAbortCallback(huart->hdmarx);
			}
		}
		//else
		{
			/* Reset Rx transfer counter */
			huart->RxXferCount = 0x00U;

			/* Restore huart->RxState to Ready */
			huart->RxState = HAL_UART_STATE_READY;

			/* As no DMA to be aborted, call directly user Abort complete callback */
			//HAL_UART_AbortReceiveCpltCallback(huart);
		}
	}
	else
	{
		/* Reset Rx transfer counter */
		huart->RxXferCount = 0x00U;

		/* Restore huart->RxState to Ready */
		huart->RxState = HAL_UART_STATE_READY;

		/* As no DMA to be aborted, call directly user Abort complete callback */
		//HAL_UART_AbortReceiveCpltCallback(huart);
	}

	return HAL_OK;
}

//------------------------------IRQ HANDLER FUNCS------------------------------
void HAL_GPIO_EXTI_Callback(uint16_t GPIO_Pin)
{
	//RX_NIRQ
	if(GPIO_Pin==GPIO_PIN_5 && r_initd==1)
	{
		RX_Interrupts(RX_ints);	//check pending interrupt flags

		//PACKET_RX_PEND flag set?
		if(RX_ints[2]&(1<<4))
		{
			HAL_GPIO_TogglePin(LED_0_GPIO_Port, LED_0_Pin);
			RX_ReadRxDataBuff(PLOAD_LEN, rcv_buff);
			RX_ClearFIFO(3);

			content_type=(rcv_buff[0]>>6)&3;
			encr_type=(rcv_buff[0]>>4)&3;

			uint32_t now_id_from=(rcv_buff[19]<<16) | (rcv_buff[20]<<8) | rcv_buff[21];
			uint32_t now_id_to=(rcv_buff[22]<<16) | (rcv_buff[23]<<8) | rcv_buff[24];

			TX_TxData(rcv_buff, PLOAD_LEN, 0);
			HAL_UART_Transmit(&huart1, "A", 1, 100); //TODO: append full "AT+FRAME=..\r\n"
			HAL_UART_Transmit_DMA(&huart1, rcv_buff, PLOAD_LEN);

			if(last_id_from!=now_id_from)
				last_id_from=now_id_from;
			if(last_id_to!=now_id_to)
				last_id_to=now_id_to;

			uint8_t s[20];
			if(!encr_type)
			{
				sprintf(s, "->  %07d  ", last_id_from);
				LCD_PutStrFast(102, 2, s, 1);
				sprintf(s, "<-  %07d  ", last_id_to);
				LCD_PutStrFast(102, 3, s, 1);
				LCD_PutStrFast(102+4*6, 0, "    ", 1);
			}
			else
			{
				LCD_PutStrFast(102, 2, "-> (UNKNOWN)", 1);
				LCD_PutStrFast(102, 3, "<- (UNKNOWN)", 1);
				LCD_PutStrFast(102+4*6, 0, "ENCR", 1);
			}

		}

		//clear pending flags
		RX_Interrupts(NULL);
	}
	else if(GPIO_Pin==TAMPER_Pin)
	{
		Tamper_check();
	}
}

void HAL_UART_RxCpltCallback(UART_HandleTypeDef *huart)
{
	if(huart->Instance==USART1)
	{
		rx_cnt++;

		if(rx_buff[0]=='A' && rx_buff[1]=='T' && rx_buff[2]=='+')
		{
			if(rx_buff[3]=='F' && rx_buff[4]=='R')
			{
				if(rx_buff[5]=='A' && rx_buff[6]=='M' && rx_buff[7]=='E' && rx_buff[PLOAD_LEN+9]=='\r' && rx_buff[PLOAD_LEN+10]=='\n')
				{
					HAL_TIM_Base_Stop_IT(&htim6);
					TIM6->CNT=0;
					TX_TxData(&rx_buff[9], PLOAD_LEN, 0);
					memset(rx_buff, 0, UART_BUFF_LEN);
					rx_cnt=0;
					HAL_UART_Receive_IT(&huart1, rx_buff, 1);
				}
			}
		}

		HAL_UART_Receive_IT(&huart1, &rx_buff[rx_cnt], 1);
		TIM6->CNT=0;
		HAL_TIM_Base_Start_IT(&htim6);
	}
}

void HAL_TIM_PeriodElapsedCallback(TIM_HandleTypeDef *htim)
{
	if(htim->Instance==TIM6)
	{
		if(tim_6_initd)
		{
			HAL_UART_AbortReceive_IT(&huart1);
			HAL_TIM_Base_Stop_IT(&htim6);
			TIM6->CNT=0;
			memset(rx_buff, 0, UART_BUFF_LEN);
			rx_cnt=0;
			HAL_UART_Receive_IT(&huart1, rx_buff, 1);
		}
		else
		{
			HAL_TIM_Base_Stop_IT(&htim6);
			TIM6->CNT=0;
			tim_6_initd=1;
		}
	}
}
/* USER CODE END PFP */

int main(void)
{

  /* MCU Configuration----------------------------------------------------------*/

  /* Reset of all peripherals, Initializes the Flash interface and the Systick. */
  HAL_Init();

  /* Configure the system clock */
  SystemClock_Config();

  /* Initialize all configured peripherals */
  MX_GPIO_Init();
  MX_DMA_Init();
  MX_ADC1_Init();
  MX_DAC_Init();
  MX_SPI2_Init();
  MX_TIM4_Init();
  MX_USART1_UART_Init();
  MX_SPI1_Init();
  MX_TIM3_Init();
  MX_TIM6_Init();
  /* USER CODE BEGIN 2 */
  memset(rx_buff, 0, UART_BUFF_LEN);
  memset(tx_buff, 0, UART_BUFF_LEN);
  //HAL_TIM_Base_Start_IT(&htim6);
  HAL_UART_Receive_IT(&huart1, rx_buff, 1);
  HAL_Delay(100);

  HAL_GPIO_WritePin(LCD_CS1_GPIO_Port, LCD_CS1_Pin, 0);
  HAL_GPIO_WritePin(LCD_CS2_GPIO_Port, LCD_CS2_Pin, 0);
  HAL_GPIO_WritePin(LCD_CS3_GPIO_Port, LCD_CS3_Pin, 0);

  LCD_Init();
  LCD_Clear();

  RX_Reset();
  TX_Reset();

  if(RX_Check() || TX_Check())	//fucked up comms with either one of Si4463
  {
	  while(1)
	  {
		  HAL_GPIO_TogglePin(LED_5_GPIO_Port, LED_5_Pin);
		  HAL_Delay(200);
	  }
  }

  RX_StartupConfig(); TX_StartupConfig();
  RX_Interrupts(NULL); TX_Interrupts(NULL);
  RX_FreqSet(rx_freq); TX_FreqSet(tx_freq);
  RX_Sleep(); TX_Sleep();
  RX_StartRx(0, PLOAD_LEN);
  TX_SetTxPower(3);//MAX_TX_POWER);
  r_initd=1;

  LCD_Blight(50); //50
  //L_Fan_RPM(20);
  //R_Fan_RPM(20);

  LCD_PutStrFast(0, 0, "SR5MS", 2); LCD_PutStrFast(102, 0, "ACT", 1);

  uint8_t line[20];
  sprintf(line, "RX %d", rx_freq);
  memmove(&line[7], &line[6], 4);
  line[6]='.';
  sprintf(&line[11], "MHz");
  LCD_PutStrFast(0, 2, line, 1);
  sprintf(line, "TX %d", tx_freq);
  memmove(&line[7], &line[6], 4);
  line[6]='.';
  sprintf(&line[11], "MHz");
  LCD_PutStrFast(0, 3, line, 1);

  Tamper_check();
  HAL_UART_Transmit(&huart1, "BOOT_OK\n", 9, 100);

  /* USER CODE END 2 */

  /* Infinite loop */
  /* USER CODE BEGIN WHILE */
  while (1)
  {
	  HAL_GPIO_TogglePin(LED_0_GPIO_Port, LED_0_Pin);
	  HAL_Delay(200);
	  //TX_TxData("1234567890123456789012345678901234567890123456789012345678901234567890123456789012345678901234567", PLOAD_LEN, 0);
  /* USER CODE END WHILE */

  }

}

void SystemClock_Config(void)
{

  RCC_OscInitTypeDef RCC_OscInitStruct;
  RCC_ClkInitTypeDef RCC_ClkInitStruct;
  RCC_PeriphCLKInitTypeDef PeriphClkInitStruct;

    /**Configure the main internal regulator output voltage
    */
  __HAL_RCC_PWR_CLK_ENABLE();

  __HAL_PWR_VOLTAGESCALING_CONFIG(PWR_REGULATOR_VOLTAGE_SCALE1);

    /**Initializes the CPU, AHB and APB busses clocks
    */
  RCC_OscInitStruct.OscillatorType = RCC_OSCILLATORTYPE_HSE;
  RCC_OscInitStruct.HSEState = RCC_HSE_BYPASS;
  RCC_OscInitStruct.PLL.PLLState = RCC_PLL_ON;
  RCC_OscInitStruct.PLL.PLLSource = RCC_PLLSOURCE_HSE;
  RCC_OscInitStruct.PLL.PLLM = 8;
  RCC_OscInitStruct.PLL.PLLN = 216;
  RCC_OscInitStruct.PLL.PLLP = RCC_PLLP_DIV2;
  RCC_OscInitStruct.PLL.PLLQ = 2;
  if (HAL_RCC_OscConfig(&RCC_OscInitStruct) != HAL_OK)
  {
    _Error_Handler(__FILE__, __LINE__);
  }

    /**Activate the Over-Drive mode
    */
  if (HAL_PWREx_EnableOverDrive() != HAL_OK)
  {
    _Error_Handler(__FILE__, __LINE__);
  }

    /**Initializes the CPU, AHB and APB busses clocks
    */
  RCC_ClkInitStruct.ClockType = RCC_CLOCKTYPE_HCLK|RCC_CLOCKTYPE_SYSCLK
                              |RCC_CLOCKTYPE_PCLK1|RCC_CLOCKTYPE_PCLK2;
  RCC_ClkInitStruct.SYSCLKSource = RCC_SYSCLKSOURCE_PLLCLK;
  RCC_ClkInitStruct.AHBCLKDivider = RCC_SYSCLK_DIV1;
  RCC_ClkInitStruct.APB1CLKDivider = RCC_HCLK_DIV4;
  RCC_ClkInitStruct.APB2CLKDivider = RCC_HCLK_DIV2;

  if (HAL_RCC_ClockConfig(&RCC_ClkInitStruct, FLASH_LATENCY_7) != HAL_OK)
  {
    _Error_Handler(__FILE__, __LINE__);
  }

  PeriphClkInitStruct.PeriphClockSelection = RCC_PERIPHCLK_USART1;
  PeriphClkInitStruct.Usart1ClockSelection = RCC_USART1CLKSOURCE_PCLK2;
  if (HAL_RCCEx_PeriphCLKConfig(&PeriphClkInitStruct) != HAL_OK)
  {
    _Error_Handler(__FILE__, __LINE__);
  }

    /**Configure the Systick interrupt time
    */
  HAL_SYSTICK_Config(HAL_RCC_GetHCLKFreq()/1000);

    /**Configure the Systick
    */
  HAL_SYSTICK_CLKSourceConfig(SYSTICK_CLKSOURCE_HCLK);

  /* SysTick_IRQn interrupt configuration */
  HAL_NVIC_SetPriority(SysTick_IRQn, 0, 0);
}

/* ADC1 init function */
static void MX_ADC1_Init(void)
{

  ADC_ChannelConfTypeDef sConfig;

    /**Configure the global features of the ADC (Clock, Resolution, Data Alignment and number of conversion)
    */
  hadc1.Instance = ADC1;
  hadc1.Init.ClockPrescaler = ADC_CLOCK_SYNC_PCLK_DIV4;
  hadc1.Init.Resolution = ADC_RESOLUTION_12B;
  hadc1.Init.ScanConvMode = ADC_SCAN_DISABLE;
  hadc1.Init.ContinuousConvMode = DISABLE;
  hadc1.Init.DiscontinuousConvMode = DISABLE;
  hadc1.Init.ExternalTrigConvEdge = ADC_EXTERNALTRIGCONVEDGE_NONE;
  hadc1.Init.ExternalTrigConv = ADC_SOFTWARE_START;
  hadc1.Init.DataAlign = ADC_DATAALIGN_RIGHT;
  hadc1.Init.NbrOfConversion = 1;
  hadc1.Init.DMAContinuousRequests = DISABLE;
  hadc1.Init.EOCSelection = ADC_EOC_SINGLE_CONV;
  if (HAL_ADC_Init(&hadc1) != HAL_OK)
  {
    _Error_Handler(__FILE__, __LINE__);
  }

    /**Configure for the selected ADC regular channel its corresponding rank in the sequencer and its sample time.
    */
  sConfig.Channel = ADC_CHANNEL_0;
  sConfig.Rank = ADC_REGULAR_RANK_1;
  sConfig.SamplingTime = ADC_SAMPLETIME_3CYCLES;
  if (HAL_ADC_ConfigChannel(&hadc1, &sConfig) != HAL_OK)
  {
    _Error_Handler(__FILE__, __LINE__);
  }

}

/* DAC init function */
static void MX_DAC_Init(void)
{

  DAC_ChannelConfTypeDef sConfig;

    /**DAC Initialization
    */
  hdac.Instance = DAC;
  if (HAL_DAC_Init(&hdac) != HAL_OK)
  {
    _Error_Handler(__FILE__, __LINE__);
  }

    /**DAC channel OUT1 config
    */
  sConfig.DAC_Trigger = DAC_TRIGGER_NONE;
  sConfig.DAC_OutputBuffer = DAC_OUTPUTBUFFER_ENABLE;
  if (HAL_DAC_ConfigChannel(&hdac, &sConfig, DAC_CHANNEL_1) != HAL_OK)
  {
    _Error_Handler(__FILE__, __LINE__);
  }

}

/* SPI1 init function */
static void MX_SPI1_Init(void)
{

  /* SPI1 parameter configuration*/
  hspi1.Instance = SPI1;
  hspi1.Init.Mode = SPI_MODE_MASTER;
  hspi1.Init.Direction = SPI_DIRECTION_2LINES;
  hspi1.Init.DataSize = SPI_DATASIZE_8BIT;
  hspi1.Init.CLKPolarity = SPI_POLARITY_LOW;
  hspi1.Init.CLKPhase = SPI_PHASE_1EDGE;
  hspi1.Init.NSS = SPI_NSS_SOFT;
  hspi1.Init.BaudRatePrescaler = SPI_BAUDRATEPRESCALER_64;
  hspi1.Init.FirstBit = SPI_FIRSTBIT_MSB;
  hspi1.Init.TIMode = SPI_TIMODE_DISABLE;
  hspi1.Init.CRCCalculation = SPI_CRCCALCULATION_DISABLE;
  hspi1.Init.CRCPolynomial = 7;
  hspi1.Init.CRCLength = SPI_CRC_LENGTH_DATASIZE;
  hspi1.Init.NSSPMode = SPI_NSS_PULSE_DISABLE;
  if (HAL_SPI_Init(&hspi1) != HAL_OK)
  {
    _Error_Handler(__FILE__, __LINE__);
  }

}

/* SPI2 init function */
static void MX_SPI2_Init(void)
{

  /* SPI2 parameter configuration*/
  hspi2.Instance = SPI2;
  hspi2.Init.Mode = SPI_MODE_MASTER;
  hspi2.Init.Direction = SPI_DIRECTION_2LINES;
  hspi2.Init.DataSize = SPI_DATASIZE_8BIT;
  hspi2.Init.CLKPolarity = SPI_POLARITY_LOW;
  hspi2.Init.CLKPhase = SPI_PHASE_1EDGE;
  hspi2.Init.NSS = SPI_NSS_SOFT;
  hspi2.Init.BaudRatePrescaler = SPI_BAUDRATEPRESCALER_32;
  hspi2.Init.FirstBit = SPI_FIRSTBIT_MSB;
  hspi2.Init.TIMode = SPI_TIMODE_DISABLE;
  hspi2.Init.CRCCalculation = SPI_CRCCALCULATION_DISABLE;
  hspi2.Init.CRCPolynomial = 7;
  hspi2.Init.CRCLength = SPI_CRC_LENGTH_DATASIZE;
  hspi2.Init.NSSPMode = SPI_NSS_PULSE_DISABLE;
  if (HAL_SPI_Init(&hspi2) != HAL_OK)
  {
    _Error_Handler(__FILE__, __LINE__);
  }

}

/* TIM3 init function */
static void MX_TIM3_Init(void)
{

  TIM_Encoder_InitTypeDef sConfig;
  TIM_MasterConfigTypeDef sMasterConfig;

  htim3.Instance = TIM3;
  htim3.Init.Prescaler = 0;
  htim3.Init.CounterMode = TIM_COUNTERMODE_UP;
  htim3.Init.Period = 0;
  htim3.Init.ClockDivision = TIM_CLOCKDIVISION_DIV1;
  htim3.Init.AutoReloadPreload = TIM_AUTORELOAD_PRELOAD_DISABLE;
  sConfig.EncoderMode = TIM_ENCODERMODE_TI1;
  sConfig.IC1Polarity = TIM_ICPOLARITY_RISING;
  sConfig.IC1Selection = TIM_ICSELECTION_DIRECTTI;
  sConfig.IC1Prescaler = TIM_ICPSC_DIV1;
  sConfig.IC1Filter = 0;
  sConfig.IC2Polarity = TIM_ICPOLARITY_RISING;
  sConfig.IC2Selection = TIM_ICSELECTION_DIRECTTI;
  sConfig.IC2Prescaler = TIM_ICPSC_DIV1;
  sConfig.IC2Filter = 0;
  if (HAL_TIM_Encoder_Init(&htim3, &sConfig) != HAL_OK)
  {
    _Error_Handler(__FILE__, __LINE__);
  }

  sMasterConfig.MasterOutputTrigger = TIM_TRGO_RESET;
  sMasterConfig.MasterSlaveMode = TIM_MASTERSLAVEMODE_DISABLE;
  if (HAL_TIMEx_MasterConfigSynchronization(&htim3, &sMasterConfig) != HAL_OK)
  {
    _Error_Handler(__FILE__, __LINE__);
  }

}

/* TIM4 init function */
static void MX_TIM4_Init(void)
{

  TIM_ClockConfigTypeDef sClockSourceConfig;
  TIM_MasterConfigTypeDef sMasterConfig;
  TIM_OC_InitTypeDef sConfigOC;

  htim4.Instance = TIM4;
  htim4.Init.Prescaler = 2159;
  htim4.Init.CounterMode = TIM_COUNTERMODE_UP;
  htim4.Init.Period = 99;
  htim4.Init.ClockDivision = TIM_CLOCKDIVISION_DIV1;
  htim4.Init.AutoReloadPreload = TIM_AUTORELOAD_PRELOAD_DISABLE;
  if (HAL_TIM_Base_Init(&htim4) != HAL_OK)
  {
    _Error_Handler(__FILE__, __LINE__);
  }

  sClockSourceConfig.ClockSource = TIM_CLOCKSOURCE_INTERNAL;
  if (HAL_TIM_ConfigClockSource(&htim4, &sClockSourceConfig) != HAL_OK)
  {
    _Error_Handler(__FILE__, __LINE__);
  }

  if (HAL_TIM_PWM_Init(&htim4) != HAL_OK)
  {
    _Error_Handler(__FILE__, __LINE__);
  }

  sMasterConfig.MasterOutputTrigger = TIM_TRGO_RESET;
  sMasterConfig.MasterSlaveMode = TIM_MASTERSLAVEMODE_DISABLE;
  if (HAL_TIMEx_MasterConfigSynchronization(&htim4, &sMasterConfig) != HAL_OK)
  {
    _Error_Handler(__FILE__, __LINE__);
  }

  sConfigOC.OCMode = TIM_OCMODE_PWM1;
  sConfigOC.Pulse = 0;
  sConfigOC.OCPolarity = TIM_OCPOLARITY_HIGH;
  sConfigOC.OCFastMode = TIM_OCFAST_DISABLE;
  if (HAL_TIM_PWM_ConfigChannel(&htim4, &sConfigOC, TIM_CHANNEL_1) != HAL_OK)
  {
    _Error_Handler(__FILE__, __LINE__);
  }

  if (HAL_TIM_PWM_ConfigChannel(&htim4, &sConfigOC, TIM_CHANNEL_2) != HAL_OK)
  {
    _Error_Handler(__FILE__, __LINE__);
  }

  if (HAL_TIM_PWM_ConfigChannel(&htim4, &sConfigOC, TIM_CHANNEL_3) != HAL_OK)
  {
    _Error_Handler(__FILE__, __LINE__);
  }

  HAL_TIM_MspPostInit(&htim4);

}

/* TIM6 init function */
static void MX_TIM6_Init(void)
{

  TIM_MasterConfigTypeDef sMasterConfig;

  htim6.Instance = TIM6;
  htim6.Init.Prescaler = 21599;
  htim6.Init.CounterMode = TIM_COUNTERMODE_UP;
  htim6.Init.Period = 1999;
  htim6.Init.AutoReloadPreload = TIM_AUTORELOAD_PRELOAD_DISABLE;
  if (HAL_TIM_Base_Init(&htim6) != HAL_OK)
  {
    _Error_Handler(__FILE__, __LINE__);
  }

  sMasterConfig.MasterOutputTrigger = TIM_TRGO_UPDATE;
  sMasterConfig.MasterSlaveMode = TIM_MASTERSLAVEMODE_DISABLE;
  if (HAL_TIMEx_MasterConfigSynchronization(&htim6, &sMasterConfig) != HAL_OK)
  {
    _Error_Handler(__FILE__, __LINE__);
  }

}

/* USART1 init function */
static void MX_USART1_UART_Init(void)
{

  huart1.Instance = USART1;
  huart1.Init.BaudRate = 115200;
  huart1.Init.WordLength = UART_WORDLENGTH_8B;
  huart1.Init.StopBits = UART_STOPBITS_1;
  huart1.Init.Parity = UART_PARITY_NONE;
  huart1.Init.Mode = UART_MODE_TX_RX;
  huart1.Init.HwFlowCtl = UART_HWCONTROL_NONE;
  huart1.Init.OverSampling = UART_OVERSAMPLING_16;
  huart1.Init.OneBitSampling = UART_ONE_BIT_SAMPLE_DISABLE;
  huart1.AdvancedInit.AdvFeatureInit = UART_ADVFEATURE_NO_INIT;
  if (HAL_UART_Init(&huart1) != HAL_OK)
  {
    _Error_Handler(__FILE__, __LINE__);
  }

}

static void MX_DMA_Init(void)
{
  /* DMA controller clock enable */
  __HAL_RCC_DMA2_CLK_ENABLE();

  /* DMA interrupt init */
  /* DMA2_Stream7_IRQn interrupt configuration */
  HAL_NVIC_SetPriority(DMA2_Stream7_IRQn, 0, 0);
  HAL_NVIC_EnableIRQ(DMA2_Stream7_IRQn);

}

/** Configure pins as
        * Analog
        * Input
        * Output
        * EVENT_OUT
        * EXTI
*/
static void MX_GPIO_Init(void)
{

  GPIO_InitTypeDef GPIO_InitStruct;

  /* GPIO Ports Clock Enable */
  __HAL_RCC_GPIOE_CLK_ENABLE();
  __HAL_RCC_GPIOH_CLK_ENABLE();
  __HAL_RCC_GPIOC_CLK_ENABLE();
  __HAL_RCC_GPIOA_CLK_ENABLE();
  __HAL_RCC_GPIOB_CLK_ENABLE();
  __HAL_RCC_GPIOD_CLK_ENABLE();

  /*Configure GPIO pin Output Level */
  HAL_GPIO_WritePin(GPIOE, TP7_Pin|TP8_Pin|LCD_E_Pin|LCD_DB0_Pin
                          |LCD_DB1_Pin|LCD_DB2_Pin|LCD_DB3_Pin|LCD_DB4_Pin
                          |LCD_DB5_Pin|LCD_DB6_Pin|LCD_DB7_Pin, GPIO_PIN_RESET);

  /*Configure GPIO pin Output Level */
  HAL_GPIO_WritePin(GPIOC, LCD_CS1_Pin|LCD_CS2_Pin|LCD_CS3_Pin|LED_1_Pin
                          |LED_2_Pin|LED_3_Pin, GPIO_PIN_RESET);

  /*Configure GPIO pin Output Level */
  HAL_GPIO_WritePin(RX_CS_GPIO_Port, RX_CS_Pin, GPIO_PIN_SET);

  /*Configure GPIO pin Output Level */
  HAL_GPIO_WritePin(GPIOB, RX_SDN_Pin|TX_SDN_Pin, GPIO_PIN_SET);

  /*Configure GPIO pin Output Level */
  HAL_GPIO_WritePin(GPIOB, LCD_RS_Pin|LCD_RW_Pin|LCD_RES_Pin, GPIO_PIN_RESET);

  /*Configure GPIO pin Output Level */
  HAL_GPIO_WritePin(TX_CS_GPIO_Port, TX_CS_Pin, GPIO_PIN_SET);

  /*Configure GPIO pin Output Level */
  HAL_GPIO_WritePin(LED_0_GPIO_Port, LED_0_Pin, GPIO_PIN_RESET);

  /*Configure GPIO pin Output Level */
  HAL_GPIO_WritePin(GPIOD, LED_4_Pin|LED_5_Pin, GPIO_PIN_RESET);

  /*Configure GPIO pins : TP7_Pin TP8_Pin */
  GPIO_InitStruct.Pin = TP7_Pin|TP8_Pin;
  GPIO_InitStruct.Mode = GPIO_MODE_OUTPUT_PP;
  GPIO_InitStruct.Pull = GPIO_NOPULL;
  GPIO_InitStruct.Speed = GPIO_SPEED_FREQ_LOW;
  HAL_GPIO_Init(GPIOE, &GPIO_InitStruct);

  /*Configure GPIO pin : TAMPER_Pin */
  GPIO_InitStruct.Pin = TAMPER_Pin;
  GPIO_InitStruct.Mode = GPIO_MODE_IT_RISING_FALLING;
  GPIO_InitStruct.Pull = GPIO_NOPULL;
  HAL_GPIO_Init(TAMPER_GPIO_Port, &GPIO_InitStruct);

  /*Configure GPIO pins : LCD_CS1_Pin LCD_CS2_Pin LCD_CS3_Pin RX_CS_Pin */
  GPIO_InitStruct.Pin = LCD_CS1_Pin|LCD_CS2_Pin|LCD_CS3_Pin|RX_CS_Pin;
  GPIO_InitStruct.Mode = GPIO_MODE_OUTPUT_PP;
  GPIO_InitStruct.Pull = GPIO_NOPULL;
  GPIO_InitStruct.Speed = GPIO_SPEED_FREQ_VERY_HIGH;
  HAL_GPIO_Init(GPIOC, &GPIO_InitStruct);

  /*Configure GPIO pin : RX_NIRQ_Pin */
  GPIO_InitStruct.Pin = RX_NIRQ_Pin;
  GPIO_InitStruct.Mode = GPIO_MODE_IT_FALLING;
  GPIO_InitStruct.Pull = GPIO_NOPULL;
  HAL_GPIO_Init(RX_NIRQ_GPIO_Port, &GPIO_InitStruct);

  /*Configure GPIO pins : RX_SDN_Pin LCD_RS_Pin LCD_RW_Pin LCD_RES_Pin
                           TX_SDN_Pin */
  GPIO_InitStruct.Pin = RX_SDN_Pin|LCD_RS_Pin|LCD_RW_Pin|LCD_RES_Pin
                          |TX_SDN_Pin;
  GPIO_InitStruct.Mode = GPIO_MODE_OUTPUT_PP;
  GPIO_InitStruct.Pull = GPIO_NOPULL;
  GPIO_InitStruct.Speed = GPIO_SPEED_FREQ_VERY_HIGH;
  HAL_GPIO_Init(GPIOB, &GPIO_InitStruct);

  /*Configure GPIO pins : LCD_E_Pin LCD_DB0_Pin LCD_DB1_Pin LCD_DB2_Pin
                           LCD_DB3_Pin LCD_DB4_Pin LCD_DB5_Pin LCD_DB6_Pin
                           LCD_DB7_Pin */
  GPIO_InitStruct.Pin = LCD_E_Pin|LCD_DB0_Pin|LCD_DB1_Pin|LCD_DB2_Pin
                          |LCD_DB3_Pin|LCD_DB4_Pin|LCD_DB5_Pin|LCD_DB6_Pin
                          |LCD_DB7_Pin;
  GPIO_InitStruct.Mode = GPIO_MODE_OUTPUT_PP;
  GPIO_InitStruct.Pull = GPIO_NOPULL;
  GPIO_InitStruct.Speed = GPIO_SPEED_FREQ_VERY_HIGH;
  HAL_GPIO_Init(GPIOE, &GPIO_InitStruct);

  /*Configure GPIO pin : TX_CS_Pin */
  GPIO_InitStruct.Pin = TX_CS_Pin;
  GPIO_InitStruct.Mode = GPIO_MODE_OUTPUT_PP;
  GPIO_InitStruct.Pull = GPIO_NOPULL;
  GPIO_InitStruct.Speed = GPIO_SPEED_FREQ_VERY_HIGH;
  HAL_GPIO_Init(TX_CS_GPIO_Port, &GPIO_InitStruct);

  /*Configure GPIO pins : TX_NIRQ_Pin BTN_3_Pin BTN_2_Pin BTN_1_Pin
                           BTN_0_Pin */
  GPIO_InitStruct.Pin = TX_NIRQ_Pin|BTN_3_Pin|BTN_2_Pin|BTN_1_Pin
                          |BTN_0_Pin;
  GPIO_InitStruct.Mode = GPIO_MODE_IT_FALLING;
  GPIO_InitStruct.Pull = GPIO_NOPULL;
  HAL_GPIO_Init(GPIOD, &GPIO_InitStruct);

  /*Configure GPIO pin : LED_0_Pin */
  GPIO_InitStruct.Pin = LED_0_Pin;
  GPIO_InitStruct.Mode = GPIO_MODE_OUTPUT_PP;
  GPIO_InitStruct.Pull = GPIO_NOPULL;
  GPIO_InitStruct.Speed = GPIO_SPEED_FREQ_LOW;
  HAL_GPIO_Init(LED_0_GPIO_Port, &GPIO_InitStruct);

  /*Configure GPIO pins : LED_1_Pin LED_2_Pin LED_3_Pin */
  GPIO_InitStruct.Pin = LED_1_Pin|LED_2_Pin|LED_3_Pin;
  GPIO_InitStruct.Mode = GPIO_MODE_OUTPUT_PP;
  GPIO_InitStruct.Pull = GPIO_NOPULL;
  GPIO_InitStruct.Speed = GPIO_SPEED_FREQ_LOW;
  HAL_GPIO_Init(GPIOC, &GPIO_InitStruct);

  /*Configure GPIO pins : LED_4_Pin LED_5_Pin */
  GPIO_InitStruct.Pin = LED_4_Pin|LED_5_Pin;
  GPIO_InitStruct.Mode = GPIO_MODE_OUTPUT_PP;
  GPIO_InitStruct.Pull = GPIO_NOPULL;
  GPIO_InitStruct.Speed = GPIO_SPEED_FREQ_LOW;
  HAL_GPIO_Init(GPIOD, &GPIO_InitStruct);

  /*Configure GPIO pins : PTT_Pin ENC_BTN_Pin */
  GPIO_InitStruct.Pin = PTT_Pin|ENC_BTN_Pin;
  GPIO_InitStruct.Mode = GPIO_MODE_IT_FALLING;
  GPIO_InitStruct.Pull = GPIO_NOPULL;
  HAL_GPIO_Init(GPIOE, &GPIO_InitStruct);

  /* EXTI interrupt init*/
  HAL_NVIC_SetPriority(EXTI0_IRQn, 0, 0);
  HAL_NVIC_EnableIRQ(EXTI0_IRQn);

  HAL_NVIC_SetPriority(EXTI1_IRQn, 0, 0);
  HAL_NVIC_EnableIRQ(EXTI1_IRQn);

  HAL_NVIC_SetPriority(EXTI2_IRQn, 0, 0);
  HAL_NVIC_EnableIRQ(EXTI2_IRQn);

  HAL_NVIC_SetPriority(EXTI3_IRQn, 0, 0);
  HAL_NVIC_EnableIRQ(EXTI3_IRQn);

  HAL_NVIC_SetPriority(EXTI4_IRQn, 0, 0);
  HAL_NVIC_EnableIRQ(EXTI4_IRQn);

  HAL_NVIC_SetPriority(EXTI9_5_IRQn, 0, 0);
  HAL_NVIC_EnableIRQ(EXTI9_5_IRQn);

}

void _Error_Handler(char *file, int line)
{
  while(1)
  {
  }
}

/************************ (C) COPYRIGHT STMicroelectronics *****END OF FILE****/
